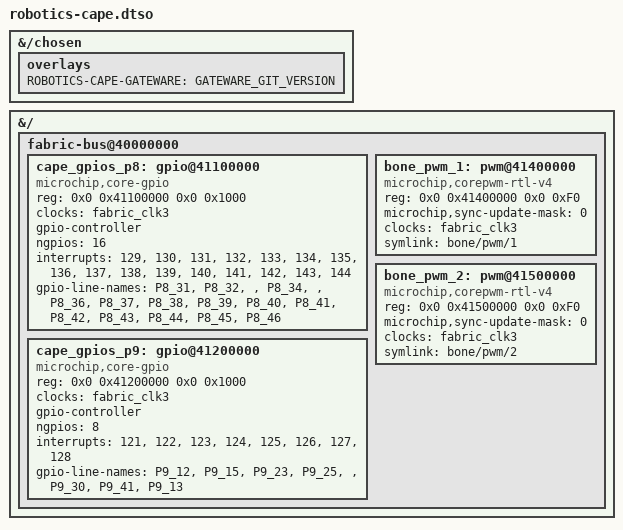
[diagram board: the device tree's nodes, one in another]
// SPDX-License-Identifier: (GPL-2.0 OR MIT)
/* Copyright (c) 2023 Microchip Technology Inc */

/dts-v1/;
/plugin/;

&{/chosen} {
	overlays {
		ROBOTICS-CAPE-GATEWARE = "GATEWARE_GIT_VERSION";
	};
};

&{/} {

	fabric-bus@40000000 {

		cape_gpios_p8: gpio@41100000 {
			compatible = "microchip,core-gpio";
			reg = <0x0 0x41100000 0x0 0x1000>;
			clocks = <&fabric_clk3>;
			gpio-controller;
			#gpio-cells = <2>;
			ngpios=<16>;
			status = "okay";
 			interrupts = <129>, <130>, <131>, <132>,
 				     <133>, <134>, <135>, <136>,
 				     <137>, <138>, <139>, <140>,
 				     <141>, <142>, <143>, <144>;

			gpio-line-names = "P8_31", "P8_32", "", "P8_34",
							  "", "P8_36", "P8_37", "P8_38",
							  "P8_39", "P8_40", "P8_41", "P8_42",
							  "P8_43", "P8_44", "P8_45", "P8_46";
		};

		cape_gpios_p9: gpio@41200000 {
			compatible = "microchip,core-gpio";
			reg = <0x0 0x41200000 0x0 0x1000>;
			clocks = <&fabric_clk3>;
			gpio-controller;
			#gpio-cells = <2>;
			ngpios=<8>;
			status = "okay";
 			interrupts = <121>, <122>, <123>, <124>,
 				     <125>, <126>, <127>, <128>;
			gpio-line-names = "P9_12", "P9_15", "P9_23", "P9_25", "", "P9_30",
							  "P9_41", "P9_13";
		};

		bone_pwm_1: pwm@41400000 {
			compatible = "microchip,corepwm-rtl-v4";
			reg = <0x0 0x41400000 0x0 0xF0>;
			microchip,sync-update-mask = /bits/ 32 <0>;
			#pwm-cells = <3>;
            status = "okay";
			clocks = <&fabric_clk3>;
			symlink = "bone/pwm/1";
		};

		bone_pwm_2: pwm@41500000 {
			compatible = "microchip,corepwm-rtl-v4";
			reg = <0x0 0x41500000 0x0 0xF0>;
			microchip,sync-update-mask = /bits/ 32 <0>;
			#pwm-cells = <3>;
            status = "okay";
			clocks = <&fabric_clk3>;
			symlink = "bone/pwm/2";
		};
	};
};

